# STM32H750 register map
File version: 2.4
CPU: CM7 r0p1, little endian, MPU, FPU, 4 interrupt priority bits
Registers are 32-bit, read-write, reset 0x0 unless marked. A register's access mark holds for its fields unless they carry their own. Offsets are from the block's base; [hi:lo] are bit positions; 'fields as' and 'values as' point back to an identical list.

## Flash
Base 0x52002000
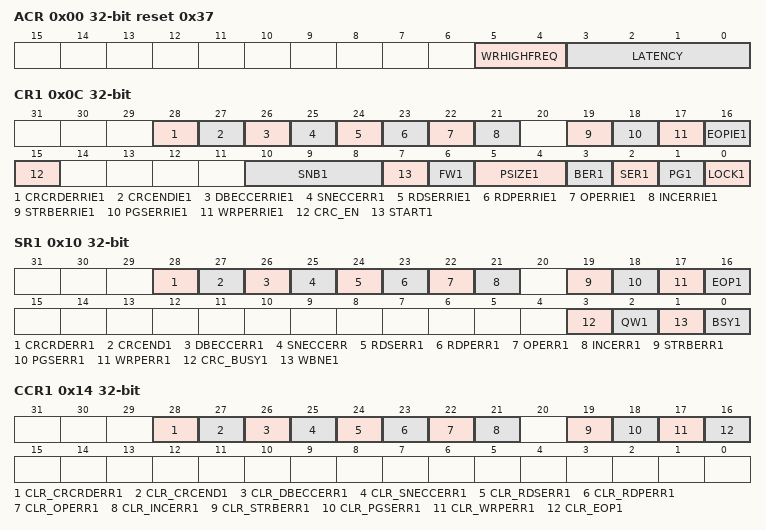
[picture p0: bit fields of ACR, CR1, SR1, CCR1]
0x00 ACR reset 0x37 — Access control register
  [5:4] WRHIGHFREQ — Flash signal delay
  [3:0] LATENCY — Read latency
0x04 KEYR1 — FLASH key register for bank 1
  [31:0] KEY1R — Bank 1 access configuration unlock key
0x08 OPTKEYR — FLASH option key register
  [31:0] OPTKEYR — Unlock key option bytes
0x0C CR1 — FLASH control register for bank 1
  [28] CRCRDERRIE1 — Bank 1 CRC read error interrupt enable bit When CRCRDERRIE1 bit is set to 1, an interrupt is generated when a protected area (PCROP or secure-only) has been detected during the last CRC computation on bank 1. CRCRDERRIE1 can be programmed only when LOCK1 is cleared to 0.
  [27] CRCENDIE1 — Bank 1 end of CRC calculation interrupt enable bit
  [26] DBECCERRIE1 — Bank 1 ECC double detection error interrupt enable bit
  [25] SNECCERR1 — Bank 1 ECC single correction error interrupt enable bit
  [24] RDSERRIE1 — Bank 1 secure error interrupt enable bit
  [23] RDPERRIE1 — Bank 1 read protection error interrupt enable bit
  [22] OPERRIE1 — Bank 1 write/erase error interrupt enable bit
  [21] INCERRIE1 — Bank 1 inconsistency error interrupt enable bit
  [19] STRBERRIE1 — Bank 1 strobe error interrupt enable bit
  [18] PGSERRIE1 — Bank 1 programming sequence error interrupt enable bit
  [17] WRPERRIE1 — Bank 1 write protection error interrupt enable bit
  [16] EOPIE1 — Bank 1 end-of-program interrupt control bit
  [15] CRC_EN — Bank 1 CRC control bit
  [10:8] SNB1 — Bank 1 sector erase selection number
  [7] START1 — Bank 1 bank or sector erase start control bit
  [6] FW1 — Bank 1 write forcing control bit
  [5:4] PSIZE1 — Bank 1 program size
  [3] BER1 — Bank 1 erase request
  [2] SER1 — Bank 1 sector erase request
  [1] PG1 — Bank 1 program enable bit
  [0] LOCK1 — Bank 1 configuration lock bit
0x10 SR1 — FLASH status register for bank 1
  [28] CRCRDERR1 ro — Bank 1 CRC read error flag CRCRDERR1 flag is raised when a word is found read protected during a CRC operation on bank 1. An interrupt is generated if CRCRDIE1 and CRCEND1 are set to 1. Writing 1 to CLR_CRCRDERR1 bit in FLASH_CCR1 register clears CRCRDERR1. Note: This flag is valid only when CRCEND1 bit is set to 1
  [27] CRCEND1 — Bank 1 CRC-complete flag
  [26] DBECCERR1 — Bank 1 ECC double detection error flag
  [25] SNECCERR — Bank 1 single correction error flag
  [24] RDSERR1 — Bank 1 secure error flag
  [23] RDPERR1 — Bank 1 read protection error flag
  [22] OPERR1 — Bank 1 write/erase error flag
  [21] INCERR1 — Bank 1 inconsistency error flag
  [19] STRBERR1 — Bank 1 strobe error flag
  [18] PGSERR1 — Bank 1 programming sequence error flag
  [17] WRPERR1 — Bank 1 write protection error flag
  [16] EOP1 — Bank 1 end-of-program flag
  [3] CRC_BUSY1 — Bank 1 CRC busy flag
  [2] QW1 — Bank 1 wait queue flag
  [1] WBNE1 — Bank 1 write buffer not empty flag
  [0] BSY1 — Bank 1 ongoing program flag
0x14 CCR1 — FLASH clear control register for bank 1
  [28] CLR_CRCRDERR1 wo — Bank 1 CRCRDERR1 flag clear bit Setting this bit to 1 resets to 0 CRCRDERR1 flag in FLASH_SR1 register.
  [27] CLR_CRCEND1 — Bank 1 CRCEND1 flag clear bit
  [26] CLR_DBECCERR1 — Bank 1 DBECCERR1 flag clear bit
  [25] CLR_SNECCERR1 — Bank 1 SNECCERR1 flag clear bit
  [24] CLR_RDSERR1 — Bank 1 RDSERR1 flag clear bit
  [23] CLR_RDPERR1 — Bank 1 RDPERR1 flag clear bit
  [22] CLR_OPERR1 — Bank 1 OPERR1 flag clear bit
  [21] CLR_INCERR1 — Bank 1 INCERR1 flag clear bit
  [19] CLR_STRBERR1 — Bank 1 STRBERR1 flag clear bit
  [18] CLR_PGSERR1 — Bank 1 PGSERR1 flag clear bi
  [17] CLR_WRPERR1 — Bank 1 WRPERR1 flag clear bit
  [16] CLR_EOP1 — Bank 1 EOP1 flag clear bit
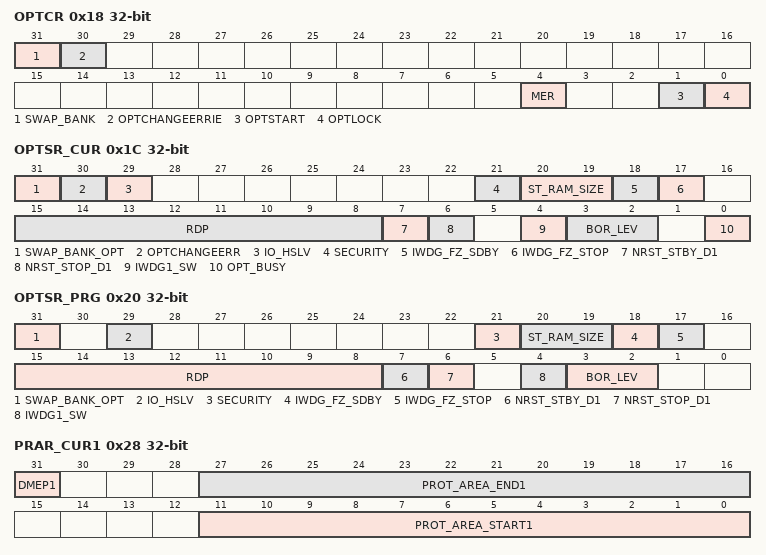
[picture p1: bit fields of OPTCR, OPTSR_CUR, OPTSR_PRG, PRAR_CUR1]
0x18 OPTCR — FLASH option control register
  [31] SWAP_BANK — Bank swapping configuration bit
  [30] OPTCHANGEERRIE — Option byte change error interrupt enable bit
  [4] MER — Flash mass erase enable bit
  [1] OPTSTART — Option byte start change option configuration bit
  [0] OPTLOCK — FLASH_OPTCR lock option configuration bit
0x1C OPTSR_CUR — FLASH option status register
  [31] SWAP_BANK_OPT — Bank swapping option status bit
  [30] OPTCHANGEERR — Option byte change error flag
  [29] IO_HSLV — I/O high-speed at low-voltage status bit (PRODUCT_BELOW_25V)
  [21] SECURITY — Security enable option status bit
  [20:19] ST_RAM_SIZE — DTCM RAM size option status
  [18] IWDG_FZ_SDBY — IWDG Standby mode freeze option status bit
  [17] IWDG_FZ_STOP — IWDG Stop mode freeze option status bit
  [15:8] RDP — Readout protection level option status byte
  [7] NRST_STBY_D1 — D1 DStandby entry reset option status bit
  [6] NRST_STOP_D1 — D1 DStop entry reset option status bit
  [4] IWDG1_SW — IWDG1 control option status bit
  [3:2] BOR_LEV — Brownout level option status bit
  [0] OPT_BUSY — Option byte change ongoing flag
0x20 OPTSR_PRG — FLASH option status register
  [31] SWAP_BANK_OPT — Bank swapping option configuration bit
  [29] IO_HSLV — I/O high-speed at low-voltage (PRODUCT_BELOW_25V)
  [21] SECURITY — Security option configuration bit
  [20:19] ST_RAM_SIZE — DTCM size select option configuration bits
  [18] IWDG_FZ_SDBY — IWDG Standby mode freeze option configuration bit
  [17] IWDG_FZ_STOP — IWDG Stop mode freeze option configuration bit
  [15:8] RDP — Readout protection level option configuration byte
  [7] NRST_STBY_D1 — Option byte erase after D1 DStandby option configuration bit
  [6] NRST_STOP_D1 — Option byte erase after D1 DStop option configuration bit
  [4] IWDG1_SW — IWDG1 option configuration bit
  [3:2] BOR_LEV — BOR reset level option configuration bits
0x24 OPTCCR wo — FLASH option clear control register
  [30] CLR_OPTCHANGEERR — OPTCHANGEERR reset bit
0x28 PRAR_CUR1 ro — FLASH protection address for bank 1
  [31] DMEP1 — Bank 1 PCROP protected erase enable option status bit
  [27:16] PROT_AREA_END1 — Bank 1 highest PCROP protected address
  [11:0] PROT_AREA_START1 — Bank 1 lowest PCROP protected address
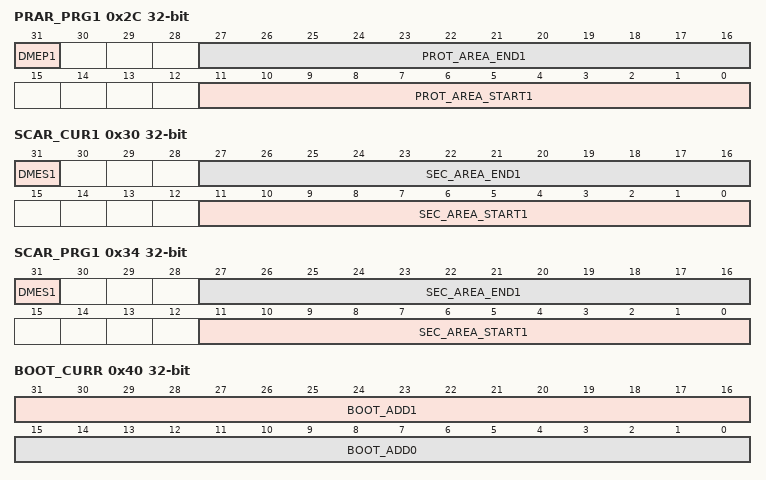
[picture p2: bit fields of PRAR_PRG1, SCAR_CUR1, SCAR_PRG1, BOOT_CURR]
0x2C PRAR_PRG1 — FLASH protection address for bank 1
  [31] DMEP1 — Bank 1 PCROP protected erase enable option configuration bit
  [27:16] PROT_AREA_END1 — Bank 1 highest PCROP protected address configuration
  [11:0] PROT_AREA_START1 — Bank 1 lowest PCROP protected address configuration
0x30 SCAR_CUR1 — FLASH secure address for bank 1
  [31] DMES1 — Bank 1 secure protected erase enable option status bit
  [27:16] SEC_AREA_END1 — Bank 1 highest secure protected address
  [11:0] SEC_AREA_START1 — Bank 1 lowest secure protected address
0x34 SCAR_PRG1 — FLASH secure address for bank 1
  [31] DMES1 — Bank 1 secure protected erase enable option configuration bit
  [27:16] SEC_AREA_END1 — Bank 1 highest secure protected address configuration
  [11:0] SEC_AREA_START1 — Bank 1 lowest secure protected address configuration
0x38 WPSN_CUR1R ro — FLASH write sector protection for bank 1
  [7:0] WRPSn1 — Bank 1 sector write protection option status byte
0x3C WPSN_PRG1R — FLASH write sector protection for bank 1
  [7:0] WRPSn1 — Bank 1 sector write protection configuration byte
0x40 BOOT_CURR ro — FLASH register with boot address
  [31:16] BOOT_ADD1 — Boot address 1
  [15:0] BOOT_ADD0 — Boot address 0
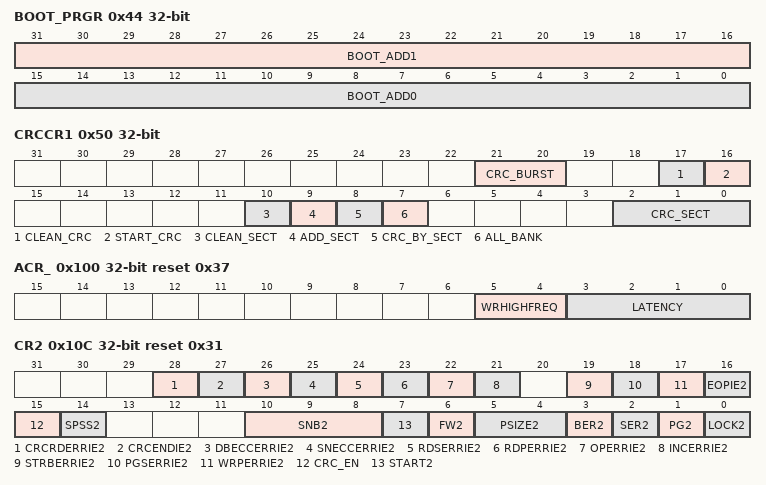
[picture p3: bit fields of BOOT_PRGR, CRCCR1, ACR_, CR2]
0x44 BOOT_PRGR ro — FLASH register with boot address
  fields as BOOT_CURR
0x50 CRCCR1 — FLASH CRC control register for bank 1
  [21:20] CRC_BURST — Bank 1 CRC burst size
  [17] CLEAN_CRC — Bank 1 CRC clear bit
  [16] START_CRC — Bank 1 CRC start bit
  [10] CLEAN_SECT — Bank 1 CRC sector list clear bit
  [9] ADD_SECT — Bank 1 CRC sector select bit
  [8] CRC_BY_SECT — Bank 1 CRC sector mode select bit
  [7] ALL_BANK — Bank 1 CRC select bit
  [2:0] CRC_SECT — Bank 1 CRC sector number
0x54 CRCSADD1R — FLASH CRC start address register for bank 1
  [19:2] CRC_START_ADDR — CRC start address on bank 1
0x58 CRCEADD1R — FLASH CRC end address register for bank 1
  [19:2] CRC_END_ADDR — CRC end address on bank 1
0x5C CRCDATAR — FLASH CRC data register
  [31:0] CRC_DATA — CRC result
0x60 ECC_FA1R ro — FLASH ECC fail address for bank 1
  [14:0] FAIL_ECC_ADDR1 — Bank 1 ECC error address
0x100 ACR_ reset 0x37 — Access control register
  [5:4] WRHIGHFREQ — Flash signal delay
  [3:0] LATENCY — Read latency
0x104 KEYR2 ro — FLASH key register for bank 2
  [31:0] KEYR2 — Bank 2 access configuration unlock key
0x108 OPTKEYR_ — FLASH option key register
  [31:0] OPTKEYR — Unlock key option bytes
0x10C CR2 reset 0x31 — FLASH control register for bank 2
  [28] CRCRDERRIE2 — Bank 2 CRC read error interrupt enable bit
  [27] CRCENDIE2 — Bank 2 end of CRC calculation interrupt enable bit
  [26] DBECCERRIE2 — Bank 2 ECC double detection error interrupt enable bit
  [25] SNECCERRIE2 — Bank 2 ECC single correction error interrupt enable bit
  [24] RDSERRIE2 — Bank 2 secure error interrupt enable bit
  [23] RDPERRIE2 — Bank 2 read protection error interrupt enable bit
  [22] OPERRIE2 — Bank 2 write/erase error interrupt enable bit
  [21] INCERRIE2 — Bank 2 inconsistency error interrupt enable bit
  [19] STRBERRIE2 — Bank 2 strobe error interrupt enable bit
  [18] PGSERRIE2 — Bank 2 programming sequence error interrupt enable bit
  [17] WRPERRIE2 — Bank 2 write protection error interrupt enable bit
  [16] EOPIE2 — Bank 2 end-of-program interrupt control bit
  [15] CRC_EN — Bank 2 CRC control bit
  [14] SPSS2 — Bank 2 special sector selection bit
  [10:8] SNB2 — Bank 2 sector erase selection number
  [7] START2 — Bank 2 bank or sector erase start control bit
  [6] FW2 — Bank 2 write forcing control bit
  [5:4] PSIZE2 — Bank 2 program size
  [3] BER2 — Bank 2 erase request
  [2] SER2 — Bank 2 sector erase request
  [1] PG2 — Bank 2 program enable bit
  [0] LOCK2 — Bank 2 configuration lock bit
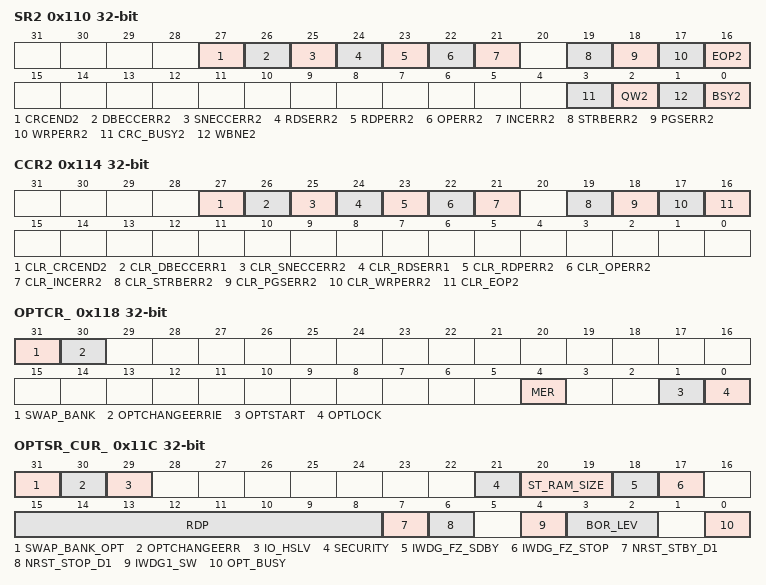
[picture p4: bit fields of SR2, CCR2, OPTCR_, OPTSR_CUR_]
0x110 SR2 — FLASH status register for bank 2
  [27] CRCEND2 — Bank 2 CRC-complete flag
  [26] DBECCERR2 — Bank 2 ECC double detection error flag
  [25] SNECCERR2 — Bank 2 single correction error flag
  [24] RDSERR2 — Bank 2 secure error flag
  [23] RDPERR2 — Bank 2 read protection error flag
  [22] OPERR2 — Bank 2 write/erase error flag
  [21] INCERR2 — Bank 2 inconsistency error flag
  [19] STRBERR2 — Bank 2 strobe error flag
  [18] PGSERR2 — Bank 2 programming sequence error flag
  [17] WRPERR2 — Bank 2 write protection error flag
  [16] EOP2 — Bank 2 end-of-program flag
  [3] CRC_BUSY2 — Bank 2 CRC busy flag
  [2] QW2 — Bank 2 wait queue flag
  [1] WBNE2 — Bank 2 write buffer not empty flag
  [0] BSY2 — Bank 2 ongoing program flag
0x114 CCR2 — FLASH clear control register for bank 2
  [27] CLR_CRCEND2 — Bank 2 CRCEND1 flag clear bit
  [26] CLR_DBECCERR1 — Bank 1 DBECCERR1 flag clear bit
  [25] CLR_SNECCERR2 — Bank 2 SNECCERR1 flag clear bit
  [24] CLR_RDSERR1 — Bank 1 RDSERR1 flag clear bit
  [23] CLR_RDPERR2 — Bank 2 RDPERR1 flag clear bit
  [22] CLR_OPERR2 — Bank 2 OPERR1 flag clear bit
  [21] CLR_INCERR2 — Bank 2 INCERR1 flag clear bit
  [19] CLR_STRBERR2 — Bank 2 STRBERR1 flag clear bit
  [18] CLR_PGSERR2 — Bank 2 PGSERR1 flag clear bi
  [17] CLR_WRPERR2 — Bank 2 WRPERR1 flag clear bit
  [16] CLR_EOP2 — Bank 1 EOP1 flag clear bit
0x118 OPTCR_ — FLASH option control register
  fields as OPTCR
0x11C OPTSR_CUR_ — FLASH option status register
  fields as OPTSR_CUR
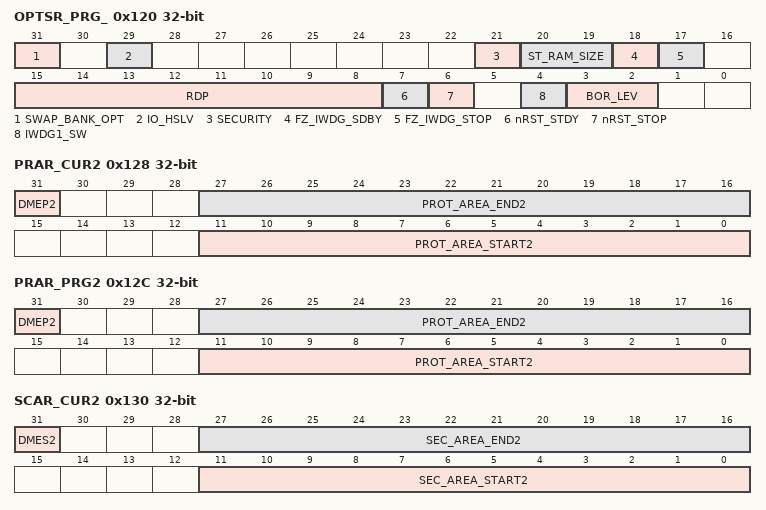
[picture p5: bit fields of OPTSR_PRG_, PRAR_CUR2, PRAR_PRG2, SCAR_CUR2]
0x120 OPTSR_PRG_ — FLASH option status register
  [31] SWAP_BANK_OPT — Bank swapping option configuration bit
  [29] IO_HSLV — I/O high-speed at low-voltage (PRODUCT_BELOW_25V)
  [21] SECURITY — Security option configuration bit
  [20:19] ST_RAM_SIZE — DTCM size select option configuration bits
  [18] FZ_IWDG_SDBY — IWDG Standby mode freeze option configuration bit
  [17] FZ_IWDG_STOP — IWDG Stop mode freeze option configuration bit
  [15:8] RDP — Readout protection level option configuration byte
  [7] nRST_STDY — Option byte erase after D1 DStandby option configuration bit
  [6] nRST_STOP — Option byte erase after D1 DStop option configuration bit
  [4] IWDG1_SW — IWDG1 option configuration bit
  [3:2] BOR_LEV — BOR reset level option configuration bits
0x124 OPTCCR_ wo — FLASH option clear control register
  [30] CLR_OPTCHANGEERR — OPTCHANGEERR reset bit
0x128 PRAR_CUR2 ro — FLASH protection address for bank 1
  [31] DMEP2 — Bank 2 PCROP protected erase enable option status bit
  [27:16] PROT_AREA_END2 — Bank 2 highest PCROP protected address
  [11:0] PROT_AREA_START2 — Bank 2 lowest PCROP protected address
0x12C PRAR_PRG2 (alternate view of PRAR_PRG1) — FLASH protection address for bank 2
  [31] DMEP2 — Bank 2 PCROP protected erase enable option configuration bit
  [27:16] PROT_AREA_END2 — Bank 2 highest PCROP protected address configuration
  [11:0] PROT_AREA_START2 — Bank 2 lowest PCROP protected address configuration
0x130 SCAR_CUR2 — FLASH secure address for bank 2
  [31] DMES2 — Bank 2 secure protected erase enable option status bit
  [27:16] SEC_AREA_END2 — Bank 2 highest secure protected address
  [11:0] SEC_AREA_START2 — Bank 2 lowest secure protected address
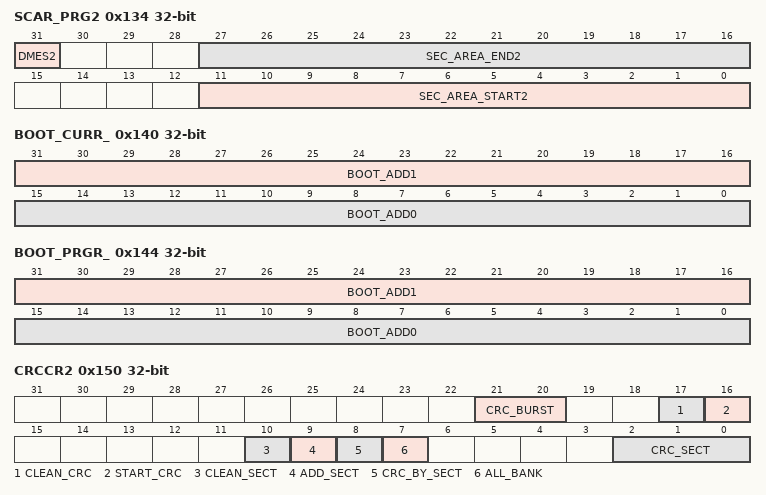
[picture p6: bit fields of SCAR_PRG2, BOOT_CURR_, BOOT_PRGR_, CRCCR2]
0x134 SCAR_PRG2 — FLASH secure address for bank 2
  [31] DMES2 — Bank 2 secure protected erase enable option configuration bit
  [27:16] SEC_AREA_END2 — Bank 2 highest secure protected address configuration
  [11:0] SEC_AREA_START2 — Bank 2 lowest secure protected address configuration
0x138 WPSN_CUR2R ro — FLASH write sector protection for bank 2
  [7:0] WRPSn2 — Bank 2 sector write protection option status byte
0x13C WPSN_PRG2R — FLASH write sector protection for bank 2
  [7:0] WRPSn2 — Bank 2 sector write protection configuration byte
0x140 BOOT_CURR_ ro — FLASH register with boot address
  fields as BOOT_CURR
0x144 BOOT_PRGR_ ro — FLASH register with boot address
  fields as BOOT_CURR
0x150 CRCCR2 — FLASH CRC control register for bank 1
  [21:20] CRC_BURST — Bank 2 CRC burst size
  [17] CLEAN_CRC — Bank 2 CRC clear bit
  [16] START_CRC — Bank 2 CRC start bit
  [10] CLEAN_SECT — Bank 2 CRC sector list clear bit
  [9] ADD_SECT — Bank 2 CRC sector select bit
  [8] CRC_BY_SECT — Bank 2 CRC sector mode select bit
  [7] ALL_BANK — Bank 2 CRC select bit
  [2:0] CRC_SECT — Bank 2 CRC sector number
0x154 CRCSADD2R — FLASH CRC start address register for bank 2
  [19:2] CRC_START_ADDR — CRC start address on bank 2
0x158 CRCEADD2R — FLASH CRC end address register for bank 2
  [19:2] CRC_END_ADDR — CRC end address on bank 2
0x15C CRCDATAR_ — FLASH CRC data register
  [31:0] CRC_DATA — CRC result
0x160 ECC_FA2R ro — FLASH ECC fail address for bank 2
  [14:0] FAIL_ECC_ADDR2 — Bank 2 ECC error address

## Notices in the file
Copyright (c) 2024 STMicroelectronics.
SPDX-License-Identifier: Apache-2.0
Licensed under the Apache License, Version 2.0 (the "License");
you may not use this file except in compliance with the License.
You may obtain a copy of the License at
http://www.apache.org/licenses/LICENSE-2.0
Unless required by applicable law or agreed to in writing, software
distributed under the License is distributed on an "AS IS" BASIS,
WITHOUT WARRANTIES OR CONDITIONS OF ANY KIND, either express or implied.
See the License for the specific language governing permissions and
limitations under the License.
